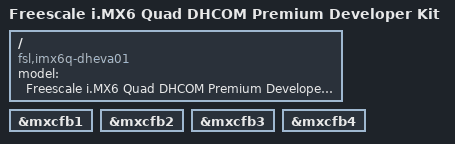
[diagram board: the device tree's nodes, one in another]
/*
 * Copyright 2014 DH electronics GmbH
 * Copyright 2013 Freescale Semiconductor, Inc.
 *
 * This program is free software; you can redistribute it and/or modify
 * it under the terms of the GNU General Public License version 2 as
 * published by the Free Software Foundation.
 */

/dts-v1/;

#include "imx6q.dtsi"
#include "imx6qdl-dhcom.dtsi"
// #include "imx6qdl-dhcom-nand.dtsi" // disables eMMC, enables NAND
// #include "imx6qdl-dhcom-weim.dtsi" // enables WEIM example config with UIO-Driver
// #include "imx6qdl-dhpico1-rs485.dtsi" // enable rs485 for UART2 (ttymxc4) on dhpico1
#include "imx6qdl-dheva01.dtsi"

/ {
	model = "Freescale i.MX6 Quad DHCOM Premium Developer Kit";
	compatible = "fsl,imx6q-dheva01", "fsl,imx6q";
};

&mxcfb1 {
	status = "okay";
};

&mxcfb2 {
	status = "okay";
};

&mxcfb3 {
	status = "okay";
};

&mxcfb4 {
	status = "okay";
};
